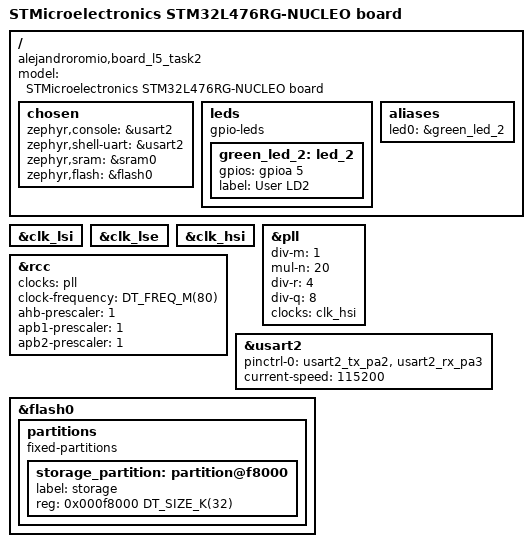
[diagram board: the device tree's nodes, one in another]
/dts-v1/;
#include <st/l4/stm32l476Xg.dtsi>
#include <st/l4/stm32l476r(c-e-g)tx-pinctrl.dtsi>

/ {
    model = "STMicroelectronics STM32L476RG-NUCLEO board";
	compatible = "alejandroromio,board_l5_task2";

	chosen {
		zephyr,console = &usart2;
		zephyr,shell-uart = &usart2;
		zephyr,sram = &sram0;
		zephyr,flash = &flash0;
	};

	leds: leds {
		compatible = "gpio-leds";

		green_led_2: led_2 {
			gpios = <&gpioa 5 GPIO_ACTIVE_HIGH>;
			label = "User LD2";
		};
	};
   
	aliases {
		led0 = &green_led_2;
	};
};

&clk_lsi {
	status = "okay";
};

&clk_lse {
	status = "okay";
};

&clk_hsi {
	status = "okay";
};

&pll {
	div-m = <1>;
	mul-n = <20>;
	div-r = <4>;
	div-q = <8>;
	clocks = <&clk_hsi>;
	status = "okay";
};

&rcc {
	clocks = <&pll>;
	clock-frequency = <DT_FREQ_M(80)>;
	ahb-prescaler = <1>;
	apb1-prescaler = <1>;
	apb2-prescaler = <1>;
};

&usart2 {
	pinctrl-0 = <&usart2_tx_pa2 &usart2_rx_pa3>;
	pinctrl-names = "default";
	current-speed = <115200>;
	status = "okay";
};

&flash0 {
	partitions {
		compatible = "fixed-partitions";
		#address-cells = <1>;
		#size-cells = <1>;

		/* Set 32KB of storage at the end of 1024KB flash */
		storage_partition: partition@f8000 {
			label = "storage";
			reg = <0x000f8000 DT_SIZE_K(32)>;
		};
	};
};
